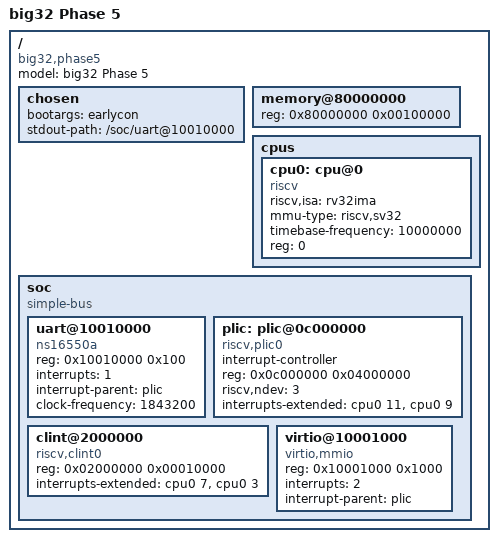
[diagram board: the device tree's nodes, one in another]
/dts-v1/;

/ {
    #address-cells = <1>;
    #size-cells = <1>;
    compatible = "big32,phase5";
    model = "big32 Phase 5";

    chosen {
        bootargs = "earlycon";
        stdout-path = "/soc/uart@10010000";
    };

    memory@80000000 {
        device_type = "memory";
        reg = <0x80000000 0x00100000>;
    };

    cpus {
        #address-cells = <1>;
        #size-cells = <0>;
        cpu0: cpu@0 {
            device_type = "cpu";
            compatible = "riscv";
            riscv,isa = "rv32ima";
            mmu-type = "riscv,sv32";
        timebase-frequency = <10000000>;
            status = "okay";
            /* reg = hartid: without it the kernel prints
               "Found CPU without hart ID" / "Unable to
               find cpu node" and falls back to the
               deprecated riscv,isa path (boot continues,
               but isa parsing finds nothing). Found from
               the attempt-5 boot log, 26 Oct 2026. */
            reg = <0>;
        };
    };

    soc {
        #address-cells = <1>;
        #size-cells = <1>;
        compatible = "simple-bus";
        ranges;

        uart@10010000 {
            compatible = "ns16550a";
            reg = <0x10010000 0x100>;
            interrupts = <1>;
            interrupt-parent = <&plic>;
            clock-frequency = <1843200>;
            status = "okay";
        };

        plic: plic@0c000000 {
            compatible = "riscv,plic0";
            #interrupt-cells = <1>;
            interrupt-controller;
            reg = <0x0c000000 0x04000000>;
            riscv,ndev = <3>;
            /* Contexts: without interrupts-extended the
               kernel's sifive-plic driver counts 0
               contexts (of_irq_count) and fails init
               with WARN_ON at irq-sifive-plic.c:449
               (seen in the attempt-5 boot log: PLIC
               unregistered, so no UART/virtio IRQs).
               M external = 11, S external = 9, hart 0. */
            interrupts-extended = <&cpu0 11 &cpu0 9>;
        };

        clint@2000000 {
            compatible = "riscv,clint0";
            reg = <0x02000000 0x00010000>;
            interrupts-extended = <&cpu0 7 &cpu0 3>;
        };

        virtio@10001000 {
            compatible = "virtio,mmio";
            reg = <0x10001000 0x1000>;
            interrupts = <2>;
            interrupt-parent = <&plic>;
        };
    };
};
